# ESP32-S3 register map
Vendor: ESPRESSIF SYSTEMS (SHANGHAI) CO., LTD.; Series: ESP32 S-Series; File version: 22
CPU: Xtensa LX7 r0p0, little endian, no MPU, FPU, 0 interrupt priority bits
Address unit: 32 bits
Registers are 32-bit, read-write, reset 0x0 unless marked. A register's access mark holds for its fields unless they carry their own. Offsets are from the block's base; [hi:lo] are bit positions; {n}, {i} and the like mark numbered series.

## SYSTEM — System Configuration Registers
Base 0x600C0000
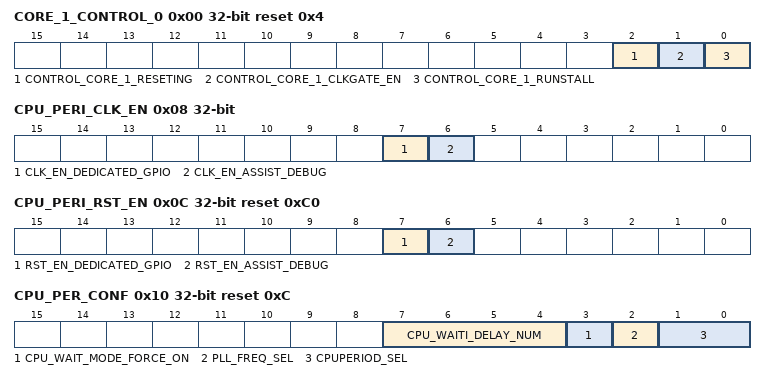
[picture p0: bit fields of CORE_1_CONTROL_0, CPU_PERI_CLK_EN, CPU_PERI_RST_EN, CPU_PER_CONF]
0x00 CORE_1_CONTROL_0 reset 0x4 — Core0 control regiter 0
  [2] CONTROL_CORE_1_RESETING — Set 1 to let core1 reset
  [1] CONTROL_CORE_1_CLKGATE_EN — Set 1 to open core1 clock
  [0] CONTROL_CORE_1_RUNSTALL — Set 1 to stall core1
0x04 CORE_1_CONTROL_1 — Core0 control regiter 1
  [31:0] CONTROL_CORE_1_MESSAGE — it's only a R/W register, no function, software can write any value
0x08 CPU_PERI_CLK_EN — cpu_peripheral clock configuration register
  [7] CLK_EN_DEDICATED_GPIO — Set 1 to open dedicated_gpio module clk
  [6] CLK_EN_ASSIST_DEBUG — Set 1 to open assist_debug module clock
0x0C CPU_PERI_RST_EN reset 0xC0 — cpu_peripheral reset configuration regsiter
  [7] RST_EN_DEDICATED_GPIO — Set 1 to let dedicated_gpio module reset
  [6] RST_EN_ASSIST_DEBUG — Set 1 to let assist_debug module reset
0x10 CPU_PER_CONF reset 0xC — cpu peripheral clock configuration register
  [7:4] CPU_WAITI_DELAY_NUM — This field used to set delay cycle when cpu enter waiti mode, after delay waiti_clk will close
  [3] CPU_WAIT_MODE_FORCE_ON — Set 1 to force cpu_waiti_clk enable.
  [2] PLL_FREQ_SEL — This field used to sel pll frequent.
  [1:0] CPUPERIOD_SEL — This field used to sel cpu clock frequent.
0x14 MEM_PD_MASK reset 0x1 — memory power down mask configuration register
  [0] LSLP_MEM_PD_MASK — Set 1 to mask memory power down.
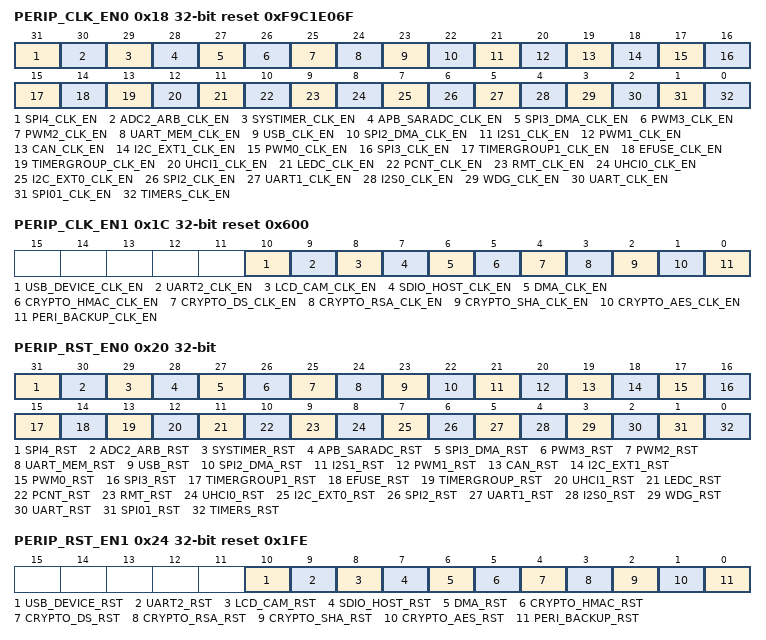
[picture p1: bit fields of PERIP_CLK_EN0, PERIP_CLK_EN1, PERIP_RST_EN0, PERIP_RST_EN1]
0x18 PERIP_CLK_EN0 reset 0xF9C1E06F — peripheral clock configuration regsiter 0
  [31] SPI4_CLK_EN — Set 1 to enable SPI4 clock
  [30] ADC2_ARB_CLK_EN — Set 1 to enable ADC2_ARB clock
  [29] SYSTIMER_CLK_EN — Set 1 to enable SYSTEMTIMER clock
  [28] APB_SARADC_CLK_EN — Set 1 to enable APB_SARADC clock
  [27] SPI3_DMA_CLK_EN — Set 1 to enable SPI4 clock
  [26] PWM3_CLK_EN — Set 1 to enable PWM3 clock
  [25] PWM2_CLK_EN — Set 1 to enable PWM2 clock
  [24] UART_MEM_CLK_EN — Set 1 to enable UART_MEM clock
  [23] USB_CLK_EN — Set 1 to enable USB clock
  [22] SPI2_DMA_CLK_EN — Set 1 to enable SPI2_DMA clock
  [21] I2S1_CLK_EN — Set 1 to enable I2S1 clock
  [20] PWM1_CLK_EN — Set 1 to enable PWM1 clock
  [19] CAN_CLK_EN — Set 1 to enable CAN clock
  [18] I2C_EXT1_CLK_EN — Set 1 to enable I2C_EXT1 clock
  [17] PWM0_CLK_EN — Set 1 to enable PWM0 clock
  [16] SPI3_CLK_EN — Set 1 to enable SPI3 clock
  [15] TIMERGROUP1_CLK_EN — Set 1 to enable TIMERGROUP1 clock
  [14] EFUSE_CLK_EN — Set 1 to enable EFUSE clock
  [13] TIMERGROUP_CLK_EN — Set 1 to enable TIMERGROUP clock
  [12] UHCI1_CLK_EN — Set 1 to enable UHCI1 clock
  [11] LEDC_CLK_EN — Set 1 to enable LEDC clock
  [10] PCNT_CLK_EN — Set 1 to enable PCNT clock
  [9] RMT_CLK_EN — Set 1 to enable RMT clock
  [8] UHCI0_CLK_EN — Set 1 to enable UHCI0 clock
  [7] I2C_EXT0_CLK_EN — Set 1 to enable I2C_EXT0 clock
  [6] SPI2_CLK_EN — Set 1 to enable SPI2 clock
  [5] UART1_CLK_EN — Set 1 to enable UART1 clock
  [4] I2S0_CLK_EN — Set 1 to enable I2S0 clock
  [3] WDG_CLK_EN — Set 1 to enable WDG clock
  [2] UART_CLK_EN — Set 1 to enable UART clock
  [1] SPI01_CLK_EN — Set 1 to enable SPI01 clock
  [0] TIMERS_CLK_EN — Set 1 to enable TIMERS clock
0x1C PERIP_CLK_EN1 reset 0x600 — peripheral clock configuration regsiter 1
  [10] USB_DEVICE_CLK_EN — Set 1 to enable USB_DEVICE clock
  [9] UART2_CLK_EN — Set 1 to enable UART2 clock
  [8] LCD_CAM_CLK_EN — Set 1 to enable LCD_CAM clock
  [7] SDIO_HOST_CLK_EN — Set 1 to enable SDIO_HOST clock
  [6] DMA_CLK_EN — Set 1 to enable DMA clock
  [5] CRYPTO_HMAC_CLK_EN — Set 1 to enable HMAC clock
  [4] CRYPTO_DS_CLK_EN — Set 1 to enable DS clock
  [3] CRYPTO_RSA_CLK_EN — Set 1 to enable RSA clock
  [2] CRYPTO_SHA_CLK_EN — Set 1 to enable SHA clock
  [1] CRYPTO_AES_CLK_EN — Set 1 to enable AES clock
  [0] PERI_BACKUP_CLK_EN — Set 1 to enable BACKUP clock
0x20 PERIP_RST_EN0 — peripheral reset configuration register0
  [31] SPI4_RST — Set 1 to let SPI4 reset
  [30] ADC2_ARB_RST — Set 1 to let ADC2_ARB reset
  [29] SYSTIMER_RST — Set 1 to let SYSTIMER reset
  [28] APB_SARADC_RST — Set 1 to let APB_SARADC reset
  [27] SPI3_DMA_RST — Set 1 to let SPI3 reset
  [26] PWM3_RST — Set 1 to let PWM3 reset
  [25] PWM2_RST — Set 1 to let PWM2 reset
  [24] UART_MEM_RST — Set 1 to let UART_MEM reset
  [23] USB_RST — Set 1 to let USB reset
  [22] SPI2_DMA_RST — Set 1 to let SPI2 reset
  [21] I2S1_RST — Set 1 to let I2S1 reset
  [20] PWM1_RST — Set 1 to let PWM1 reset
  [19] CAN_RST — Set 1 to let CAN reset
  [18] I2C_EXT1_RST — Set 1 to let I2C_EXT1 reset
  [17] PWM0_RST — Set 1 to let PWM0 reset
  [16] SPI3_RST — Set 1 to let SPI3 reset
  [15] TIMERGROUP1_RST — Set 1 to let TIMERGROUP1 reset
  [14] EFUSE_RST — Set 1 to let EFUSE reset
  [13] TIMERGROUP_RST — Set 1 to let TIMERGROUP reset
  [12] UHCI1_RST — Set 1 to let UHCI1 reset
  [11] LEDC_RST — Set 1 to let LEDC reset
  [10] PCNT_RST — Set 1 to let PCNT reset
  [9] RMT_RST — Set 1 to let RMT reset
  [8] UHCI0_RST — Set 1 to let UHCI0 reset
  [7] I2C_EXT0_RST — Set 1 to let I2C_EXT0 reset
  [6] SPI2_RST — Set 1 to let SPI2 reset
  [5] UART1_RST — Set 1 to let UART1 reset
  [4] I2S0_RST — Set 1 to let I2S0 reset
  [3] WDG_RST — Set 1 to let WDG reset
  [2] UART_RST — Set 1 to let UART reset
  [1] SPI01_RST — Set 1 to let SPI01 reset
  [0] TIMERS_RST — Set 1 to let TIMERS reset
0x24 PERIP_RST_EN1 reset 0x1FE — peripheral reset configuration regsiter 1
  [10] USB_DEVICE_RST — Set 1 to let USB_DEVICE reset
  [9] UART2_RST — Set 1 to let UART2 reset
  [8] LCD_CAM_RST — Set 1 to let LCD_CAM reset
  [7] SDIO_HOST_RST — Set 1 to let SDIO_HOST reset
  [6] DMA_RST — Set 1 to let DMA reset
  [5] CRYPTO_HMAC_RST — Set 1 to let CRYPTO_HMAC reset
  [4] CRYPTO_DS_RST — Set 1 to let CRYPTO_DS reset
  [3] CRYPTO_RSA_RST — Set 1 to let CRYPTO_RSA reset
  [2] CRYPTO_SHA_RST — Set 1 to let CRYPTO_SHA reset
  [1] CRYPTO_AES_RST — Set 1 to let CRYPTO_AES reset
  [0] PERI_BACKUP_RST — Set 1 to let BACKUP reset
0x28 BT_LPCK_DIV_INT reset 0xFF — low power clock frequent division factor configuration regsiter
  [11:0] BT_LPCK_DIV_NUM — This field is lower power clock frequent division factor
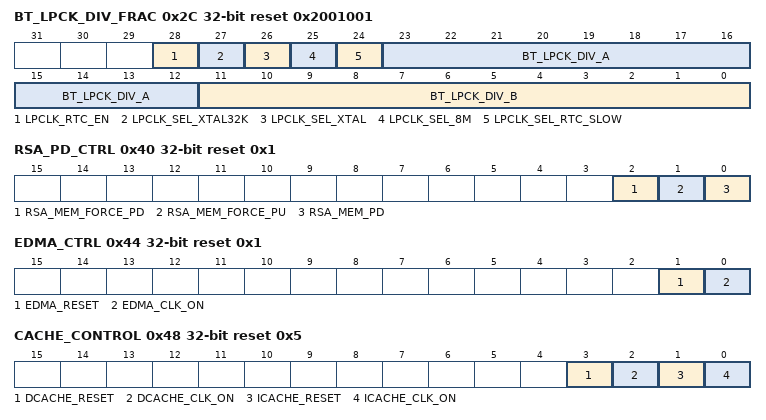
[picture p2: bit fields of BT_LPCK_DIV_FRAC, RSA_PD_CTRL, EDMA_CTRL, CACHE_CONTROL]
0x2C BT_LPCK_DIV_FRAC reset 0x2001001 — low power clock configuration register
  [28] LPCLK_RTC_EN — Set 1 to enable RTC low power clock
  [27] LPCLK_SEL_XTAL32K — Set 1 to select xtal32k clock as low power clock
  [26] LPCLK_SEL_XTAL — Set 1 to select xtal clock as rtc low power clock
  [25] LPCLK_SEL_8M — Set 1 to select 8m clock as rtc low power clock
  [24] LPCLK_SEL_RTC_SLOW — Set 1 to select rtc-slow clock as rtc low power clock
  [23:12] BT_LPCK_DIV_A — This field is lower power clock frequent division factor a
  [11:0] BT_LPCK_DIV_B — This field is lower power clock frequent division factor b
{0x30+4i} CPU_INTR_FROM_CPU_{i} (i=0..3) — interrupt source register {i}
  [0] CPU_INTR_FROM_CPU_{i} — Set 1 to generate cpu interrupt {i}
0x40 RSA_PD_CTRL reset 0x1 — rsa memory power control register
  [2] RSA_MEM_FORCE_PD — Set 1 to force power down RSA memory,this bit has the highest priority.
  [1] RSA_MEM_FORCE_PU — Set 1 to force power up RSA memory, this bit has the second highest priority.
  [0] RSA_MEM_PD — Set 1 to power down RSA memory. This bit has the lowest priority.When Digital Signature occupies the RSA, this bit is invalid.
0x44 EDMA_CTRL reset 0x1 — EDMA control register
  [1] EDMA_RESET — Set 1 to let EDMA reset
  [0] EDMA_CLK_ON — Set 1 to enable EDMA clock.
0x48 CACHE_CONTROL reset 0x5
  [3] DCACHE_RESET — Set 1 to let dcache reset
  [2] DCACHE_CLK_ON — Set 1 to enable dcache clock
  [1] ICACHE_RESET — Set 1 to let icache reset
  [0] ICACHE_CLK_ON — Set 1 to enable icache clock
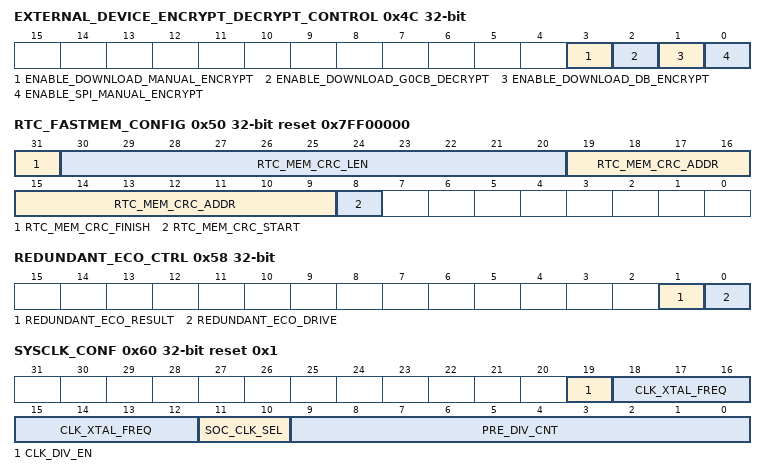
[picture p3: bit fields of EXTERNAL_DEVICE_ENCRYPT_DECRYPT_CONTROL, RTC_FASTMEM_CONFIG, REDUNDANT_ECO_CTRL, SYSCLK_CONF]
0x4C EXTERNAL_DEVICE_ENCRYPT_DECRYPT_CONTROL — External memory encrypt and decrypt control register
  [3] ENABLE_DOWNLOAD_MANUAL_ENCRYPT — Set 1 to enable download manual encrypt
  [2] ENABLE_DOWNLOAD_G0CB_DECRYPT — Set 1 to enable download G0CB decrypt
  [1] ENABLE_DOWNLOAD_DB_ENCRYPT — Set 1 to enable download DB encrypt.
  [0] ENABLE_SPI_MANUAL_ENCRYPT — Set 1 to enable the SPI manual encrypt.
0x50 RTC_FASTMEM_CONFIG access per field reset 0x7FF00000 — RTC fast memory configuration register
  [31] RTC_MEM_CRC_FINISH ro — This bit stores the status of RTC memory CRC.1 means finished.
  [30:20] RTC_MEM_CRC_LEN rw — This field is used to set length of RTC memory for CRC based on start address.
  [19:9] RTC_MEM_CRC_ADDR rw — This field is used to set address of RTC memory for CRC.
  [8] RTC_MEM_CRC_START rw — Set 1 to start the CRC of RTC memory
0x54 RTC_FASTMEM_CRC ro — RTC fast memory CRC control register
  [31:0] RTC_MEM_CRC_RES — This field stores the CRC result of RTC memory.
0x58 REDUNDANT_ECO_CTRL access per field — ******* Description ***********
  [1] REDUNDANT_ECO_RESULT ro — ******* Description ***********
  [0] REDUNDANT_ECO_DRIVE rw — ******* Description ***********
0x5C CLOCK_GATE reset 0x1 — ******* Description ***********
  [0] CLK_EN
0x60 SYSCLK_CONF access per field reset 0x1 — System clock configuration register.
  [19] CLK_DIV_EN ro — Reserved.
  [18:12] CLK_XTAL_FREQ ro — This field is used to read xtal frequency in MHz.
  [11:10] SOC_CLK_SEL rw — This field is used to select soc clock.
  [9:0] PRE_DIV_CNT rw — This field is used to set the count of prescaler of XTAL_CLK.
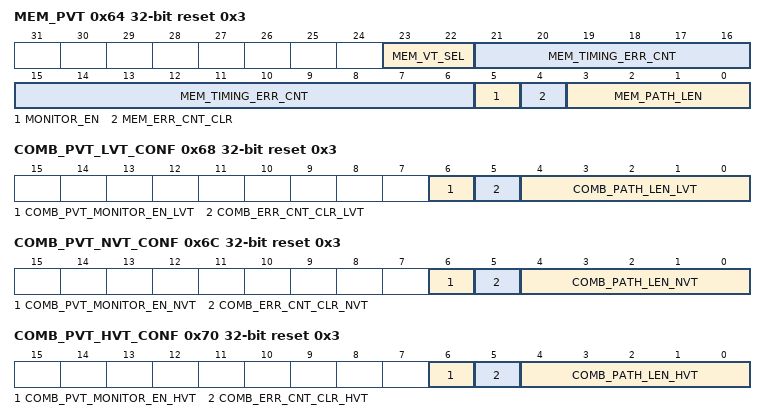
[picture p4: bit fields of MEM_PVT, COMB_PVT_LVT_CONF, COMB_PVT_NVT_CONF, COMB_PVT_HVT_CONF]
0x64 MEM_PVT access per field reset 0x3 — ******* Description ***********
  [23:22] MEM_VT_SEL rw — ******* Description ***********
  [21:6] MEM_TIMING_ERR_CNT ro — ******* Description ***********
  [5] MONITOR_EN rw — ******* Description ***********
  [4] MEM_ERR_CNT_CLR wo — ******* Description ***********
  [3:0] MEM_PATH_LEN rw — ******* Description ***********
0x68 COMB_PVT_LVT_CONF access per field reset 0x3 — ******* Description ***********
  [6] COMB_PVT_MONITOR_EN_LVT rw — ******* Description ***********
  [5] COMB_ERR_CNT_CLR_LVT wo — ******* Description ***********
  [4:0] COMB_PATH_LEN_LVT rw — ******* Description ***********
0x6C COMB_PVT_NVT_CONF access per field reset 0x3 — ******* Description ***********
  [6] COMB_PVT_MONITOR_EN_NVT rw — ******* Description ***********
  [5] COMB_ERR_CNT_CLR_NVT wo — ******* Description ***********
  [4:0] COMB_PATH_LEN_NVT rw — ******* Description ***********
0x70 COMB_PVT_HVT_CONF access per field reset 0x3 — ******* Description ***********
  [6] COMB_PVT_MONITOR_EN_HVT rw — ******* Description ***********
  [5] COMB_ERR_CNT_CLR_HVT wo — ******* Description ***********
  [4:0] COMB_PATH_LEN_HVT rw — ******* Description ***********
{0x74+0xC*i} COMB_PVT_ERR_LVT_SITE{i} ro (i=0..3) — ******* Description ***********
  [15:0] COMB_TIMING_ERR_CNT_LVT_SITE{i}
{0x78+0xC*i} COMB_PVT_ERR_NVT_SITE{i} ro (i=0..3) — ******* Description ***********
  [15:0] COMB_TIMING_ERR_CNT_NVT_SITE{i}
{0x7C+0xC*i} COMB_PVT_ERR_HVT_SITE{i} ro (i=0..3) — ******* Description ***********
  [15:0] COMB_TIMING_ERR_CNT_HVT_SITE{i}
0xFFC DATE reset 0x2101220 — version register
  [27:0] DATE
